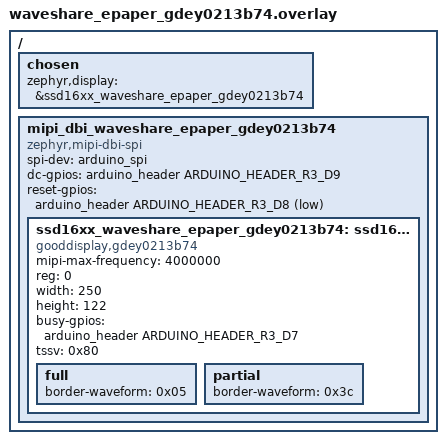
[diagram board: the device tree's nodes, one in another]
/*
 * Copyright (c) 2024, Kelly Helmut Lord
 *
 * SPDX-License-Identifier: Apache-2.0
 */

#include "waveshare_epaper_common.dtsi"
#include <zephyr/dt-bindings/gpio/arduino-header-r3.h>

/ {
	chosen {
		zephyr,display = &ssd16xx_waveshare_epaper_gdey0213b74;
	};

	mipi_dbi_waveshare_epaper_gdey0213b74 {
		compatible = "zephyr,mipi-dbi-spi";
		spi-dev = <&arduino_spi>;
		dc-gpios = <&arduino_header ARDUINO_HEADER_R3_D9 GPIO_ACTIVE_HIGH>;
		reset-gpios = <&arduino_header ARDUINO_HEADER_R3_D8 GPIO_ACTIVE_LOW>;
		#address-cells = <1>;
		#size-cells = <0>;

		ssd16xx_waveshare_epaper_gdey0213b74: ssd16xxfb@0 {
			compatible = "gooddisplay,gdey0213b74", "solomon,ssd1680";
			mipi-max-frequency = <4000000>;
			reg = <0>;
			width = <250>;
			height = <122>;
			busy-gpios = <&arduino_header ARDUINO_HEADER_R3_D7 GPIO_ACTIVE_HIGH>;

			tssv = <0x80>;

			full {
				border-waveform = <0x05>;
			};

			partial {
				border-waveform = <0x3c>;
			};
		};
	};
};
